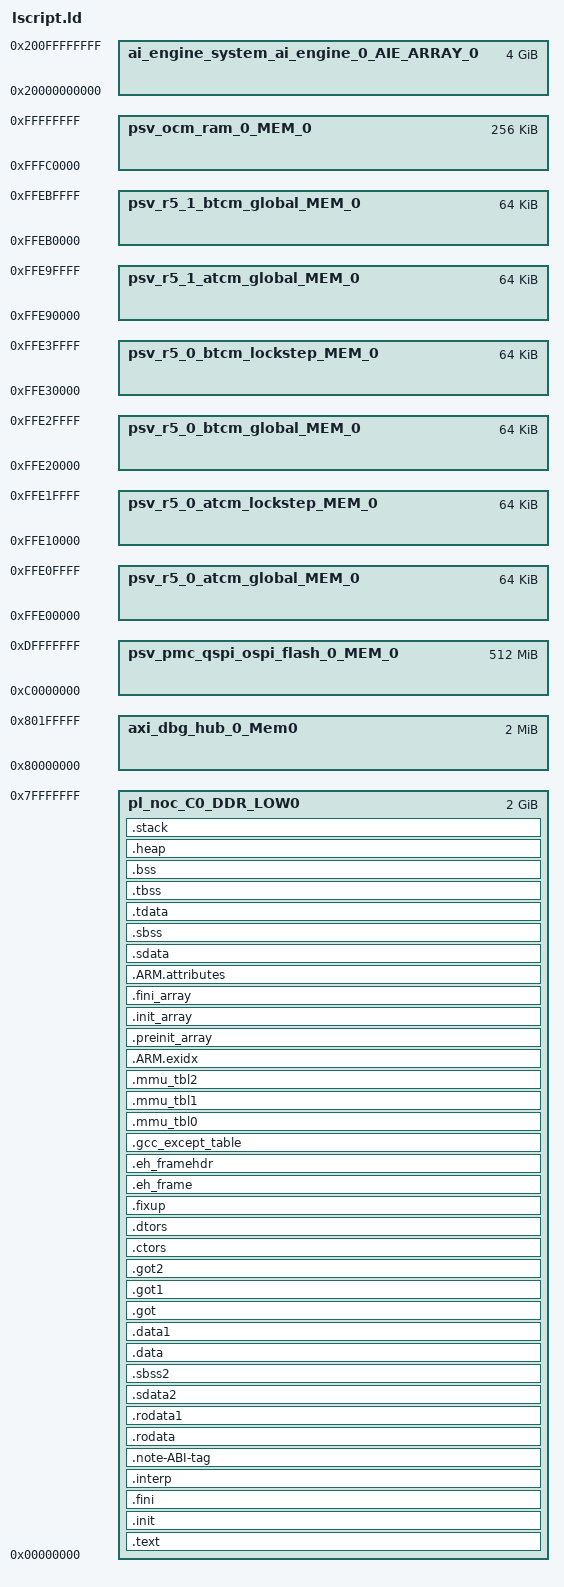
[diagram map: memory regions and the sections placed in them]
/*  © Copyright 2020 Xilinx, Inc.
 * Licensed under the Apache License, Version 2.0 (the 'License');
 * you may not use this file except in compliance with the License.
 * You may obtain a copy of the License at
 * 
 *      http://www.apache.org/licenses/LICENSE-2.0
 * 
 * Unless required by applicable law or agreed to in writing, software
 * distributed under the License is distributed on an 'AS IS' BASIS,
 * WITHOUT WARRANTIES OR CONDITIONS OF ANY KIND, either express or implied.
 * See the License for the specific language governing permissions and
 * limitations under the License.
 */

/*******************************************************************/
/*                                                                 */
/* This file is automatically generated by linker script generator.*/
/*                                                                 */
/* Version: 2019.2.2                                               */
/*                                                                 */
/* Copyright (c) 2010-2020 Xilinx, Inc.  All rights reserved.      */
/*                                                                 */
/* Description : ARM v8 Linker Script                           */
/*                                                                 */
/*******************************************************************/

_STACK_SIZE = DEFINED(_STACK_SIZE) ? _STACK_SIZE : 0x2000;
_HEAP_SIZE = DEFINED(_HEAP_SIZE) ? _HEAP_SIZE : 0x2000;

_EL0_STACK_SIZE = DEFINED(_EL0_STACK_SIZE) ? _EL0_STACK_SIZE : 1024;
_EL1_STACK_SIZE = DEFINED(_EL1_STACK_SIZE) ? _EL1_STACK_SIZE : 2048;
_EL2_STACK_SIZE = DEFINED(_EL2_STACK_SIZE) ? _EL2_STACK_SIZE : 1024;

/* Define Memories in the system */

MEMORY
{
   pl_noc_C0_DDR_LOW0 : ORIGIN = 0x0, LENGTH = 0x80000000
   axi_dbg_hub_0_Mem0 : ORIGIN = 0x80000000, LENGTH = 0x200000
   ai_engine_system_ai_engine_0_AIE_ARRAY_0 : ORIGIN = 0x20000000000, LENGTH = 0x100000000
   psv_ocm_ram_0_MEM_0 : ORIGIN = 0xFFFC0000, LENGTH = 0x40000
   psv_pmc_qspi_ospi_flash_0_MEM_0 : ORIGIN = 0xC0000000, LENGTH = 0x20000000
   psv_r5_0_atcm_global_MEM_0 : ORIGIN = 0xFFE00000, LENGTH = 0x10000
   psv_r5_0_atcm_lockstep_MEM_0 : ORIGIN = 0xFFE10000, LENGTH = 0x10000
   psv_r5_0_btcm_global_MEM_0 : ORIGIN = 0xFFE20000, LENGTH = 0x10000
   psv_r5_0_btcm_lockstep_MEM_0 : ORIGIN = 0xFFE30000, LENGTH = 0x10000
   psv_r5_1_atcm_global_MEM_0 : ORIGIN = 0xFFE90000, LENGTH = 0x10000
   psv_r5_1_btcm_global_MEM_0 : ORIGIN = 0xFFEB0000, LENGTH = 0x10000
}

/* Specify the default entry point to the program */

ENTRY(_vector_table)

/* Define the sections, and where they are mapped in memory */

SECTIONS
{
.text : {
   KEEP (*(.vectors))
   *(.boot)
   *(.text)
   *(.text.*)
   *(.gnu.linkonce.t.*)
   *(.plt)
   *(.gnu_warning)
   *(.gcc_execpt_table)
   *(.glue_7)
   *(.glue_7t)
   *(.ARM.extab)
   *(.gnu.linkonce.armextab.*)
} > pl_noc_C0_DDR_LOW0

.init (ALIGN(64)) : {
   KEEP (*(.init))
} > pl_noc_C0_DDR_LOW0

.fini (ALIGN(64)) : {
   KEEP (*(.fini))
} > pl_noc_C0_DDR_LOW0

.interp : {
   KEEP (*(.interp))
} > pl_noc_C0_DDR_LOW0

.note-ABI-tag : {
   KEEP (*(.note-ABI-tag))
} > pl_noc_C0_DDR_LOW0

.rodata : {
   . = ALIGN(64);
   __rodata_start = .;
   *(.rodata)
   *(.rodata.*)
   *(.gnu.linkonce.r.*)
   __rodata_end = .;
} > pl_noc_C0_DDR_LOW0

.rodata1 : {
   . = ALIGN(64);
   __rodata1_start = .;
   *(.rodata1)
   *(.rodata1.*)
   __rodata1_end = .;
} > pl_noc_C0_DDR_LOW0

.sdata2 : {
   . = ALIGN(64);
   __sdata2_start = .;
   *(.sdata2)
   *(.sdata2.*)
   *(.gnu.linkonce.s2.*)
   __sdata2_end = .;
} > pl_noc_C0_DDR_LOW0

.sbss2 : {
   . = ALIGN(64);
   __sbss2_start = .;
   *(.sbss2)
   *(.sbss2.*)
   *(.gnu.linkonce.sb2.*)
   __sbss2_end = .;
} > pl_noc_C0_DDR_LOW0

.data : {
   . = ALIGN(64);
   __data_start = .;
   *(.data)
   *(.data.*)
   *(.gnu.linkonce.d.*)
   *(.jcr)
   *(.got)
   *(.got.plt)
   __data_end = .;
} > pl_noc_C0_DDR_LOW0

.data1 : {
   . = ALIGN(64);
   __data1_start = .;
   *(.data1)
   *(.data1.*)
   __data1_end = .;
} > pl_noc_C0_DDR_LOW0

.got : {
   *(.got)
} > pl_noc_C0_DDR_LOW0

.got1 : {
   *(.got1)
} > pl_noc_C0_DDR_LOW0

.got2 : {
   *(.got2)
} > pl_noc_C0_DDR_LOW0

.ctors : {
   . = ALIGN(64);
   __CTOR_LIST__ = .;
   ___CTORS_LIST___ = .;
   KEEP (*crtbegin.o(.ctors))
   KEEP (*(EXCLUDE_FILE(*crtend.o) .ctors))
   KEEP (*(SORT(.ctors.*)))
   KEEP (*(.ctors))
   __CTOR_END__ = .;
   ___CTORS_END___ = .;
} > pl_noc_C0_DDR_LOW0

.dtors : {
   . = ALIGN(64);
   __DTOR_LIST__ = .;
   ___DTORS_LIST___ = .;
   KEEP (*crtbegin.o(.dtors))
   KEEP (*(EXCLUDE_FILE(*crtend.o) .dtors))
   KEEP (*(SORT(.dtors.*)))
   KEEP (*(.dtors))
   __DTOR_END__ = .;
   ___DTORS_END___ = .;
} > pl_noc_C0_DDR_LOW0

.fixup : {
   __fixup_start = .;
   *(.fixup)
   __fixup_end = .;
} > pl_noc_C0_DDR_LOW0

.eh_frame : {
   *(.eh_frame)
} > pl_noc_C0_DDR_LOW0

.eh_framehdr : {
   __eh_framehdr_start = .;
   *(.eh_framehdr)
   __eh_framehdr_end = .;
} > pl_noc_C0_DDR_LOW0

.gcc_except_table : {
   *(.gcc_except_table)
} > pl_noc_C0_DDR_LOW0

.mmu_tbl0 (ALIGN(4096)) : {
   __mmu_tbl0_start = .;
   *(.mmu_tbl0)
   __mmu_tbl0_end = .;
} > pl_noc_C0_DDR_LOW0

.mmu_tbl1 (ALIGN(4096)) : {
   __mmu_tbl1_start = .;
   *(.mmu_tbl1)
   __mmu_tbl1_end = .;
} > pl_noc_C0_DDR_LOW0

.mmu_tbl2 (ALIGN(4096)) : {
   __mmu_tbl2_start = .;
   *(.mmu_tbl2)
   __mmu_tbl2_end = .;
} > pl_noc_C0_DDR_LOW0

.ARM.exidx : {
   __exidx_start = .;
   *(.ARM.exidx*)
   *(.gnu.linkonce.armexidix.*.*)
   __exidx_end = .;
} > pl_noc_C0_DDR_LOW0

.preinit_array : {
   . = ALIGN(64);
   __preinit_array_start = .;
   KEEP (*(SORT(.preinit_array.*)))
   KEEP (*(.preinit_array))
   __preinit_array_end = .;
} > pl_noc_C0_DDR_LOW0

.init_array : {
   . = ALIGN(64);
   __init_array_start = .;
   KEEP (*(SORT(.init_array.*)))
   KEEP (*(.init_array))
   __init_array_end = .;
} > pl_noc_C0_DDR_LOW0

.fini_array : {
   . = ALIGN(64);
   __fini_array_start = .;
   KEEP (*(SORT(.fini_array.*)))
   KEEP (*(.fini_array))
   __fini_array_end = .;
} > pl_noc_C0_DDR_LOW0

.ARM.attributes : {
   __ARM.attributes_start = .;
   *(.ARM.attributes)
   __ARM.attributes_end = .;
} > pl_noc_C0_DDR_LOW0

.sdata : {
   . = ALIGN(64);
   __sdata_start = .;
   *(.sdata)
   *(.sdata.*)
   *(.gnu.linkonce.s.*)
   __sdata_end = .;
} > pl_noc_C0_DDR_LOW0

.sbss (NOLOAD) : {
   . = ALIGN(64);
   __sbss_start = .;
   *(.sbss)
   *(.sbss.*)
   *(.gnu.linkonce.sb.*)
   . = ALIGN(64);
   __sbss_end = .;
} > pl_noc_C0_DDR_LOW0

.tdata : {
   . = ALIGN(64);
   __tdata_start = .;
   *(.tdata)
   *(.tdata.*)
   *(.gnu.linkonce.td.*)
   __tdata_end = .;
} > pl_noc_C0_DDR_LOW0

.tbss : {
   . = ALIGN(64);
   __tbss_start = .;
   *(.tbss)
   *(.tbss.*)
   *(.gnu.linkonce.tb.*)
   __tbss_end = .;
} > pl_noc_C0_DDR_LOW0

.bss (NOLOAD) : {
   . = ALIGN(64);
   __bss_start__ = .;
   *(.bss)
   *(.bss.*)
   *(.gnu.linkonce.b.*)
   *(COMMON)
   . = ALIGN(64);
   __bss_end__ = .;
} > pl_noc_C0_DDR_LOW0

_SDA_BASE_ = __sdata_start + ((__sbss_end - __sdata_start) / 2 );

_SDA2_BASE_ = __sdata2_start + ((__sbss2_end - __sdata2_start) / 2 );

/* Generate Stack and Heap definitions */

.heap (NOLOAD) : {
   . = ALIGN(64);
   _heap = .;
   HeapBase = .;
   _heap_start = .;
   . += _HEAP_SIZE;
   _heap_end = .;
   HeapLimit = .;
} > pl_noc_C0_DDR_LOW0

.stack (NOLOAD) : {
   . = ALIGN(64);
   _el3_stack_end = .;
   . += _STACK_SIZE;
   __el3_stack = .;
   _el2_stack_end = .;
   . += _EL2_STACK_SIZE;
   . = ALIGN(64);
   __el2_stack = .;
   _el1_stack_end = .;
   . += _EL1_STACK_SIZE;
   . = ALIGN(64);
   __el1_stack = .;
   _el0_stack_end = .;
   . += _EL0_STACK_SIZE;
   . = ALIGN(64);
   __el0_stack = .;
} > pl_noc_C0_DDR_LOW0

_end = .;
}

